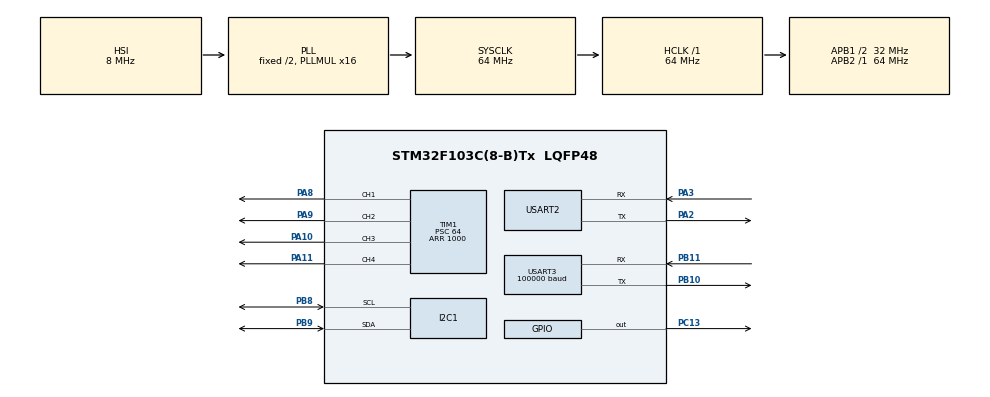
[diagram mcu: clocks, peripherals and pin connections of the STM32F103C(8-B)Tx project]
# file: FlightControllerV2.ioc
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Dma.Request0=USART3_RX
Dma.USART3_RX.0.Direction=DMA_PERIPH_TO_MEMORY
Dma.USART3_RX.0.Instance=DMA1_Channel3
Dma.USART3_RX.0.MemDataAlignment=DMA_MDATAALIGN_BYTE
Dma.USART3_RX.0.MemInc=DMA_MINC_ENABLE
Dma.USART3_RX.0.Mode=DMA_CIRCULAR
Dma.USART3_RX.0.PeriphDataAlignment=DMA_PDATAALIGN_BYTE
Dma.USART3_RX.0.PeriphInc=DMA_PINC_DISABLE
Dma.USART3_RX.0.Priority=DMA_PRIORITY_HIGH
Mcu.Family=STM32F1
Mcu.Name=STM32F103C(8-B)Tx
Mcu.Package=LQFP48
NVIC.DMA1_Channel3_IRQn=true\:1\:0\:true\:false\:true\:false
NVIC.PriorityGroup=NVIC_PRIORITYGROUP_4
NVIC.USART3_IRQn=true\:1\:0\:true\:false\:true\:true
PA10.GPIO_Speed=GPIO_SPEED_FREQ_HIGH
PA10.Signal=S_TIM1_CH3
PA11.GPIO_Speed=GPIO_SPEED_FREQ_HIGH
PA11.Signal=S_TIM1_CH4
PA13.Signal=SYS_JTMS-SWDIO
PA14.Signal=SYS_JTCK-SWCLK
PA2.Mode=Asynchronous
PA2.Signal=USART2_TX
PA3.Mode=Asynchronous
PA3.Signal=USART2_RX
PA8.GPIO_ModeDefaultPP=GPIO_MODE_AF_PP
PA8.GPIO_Speed=GPIO_SPEED_FREQ_HIGH
PA8.Signal=S_TIM1_CH1
PA9.GPIO_Speed=GPIO_SPEED_FREQ_HIGH
PA9.Signal=S_TIM1_CH2
PB10.Mode=Asynchronous
PB10.Signal=USART3_TX
PB11.Mode=Asynchronous
PB11.Signal=USART3_RX
PB8.Mode=I2C
PB8.Signal=I2C1_SCL
PB9.Mode=I2C
PB9.Signal=I2C1_SDA
PC13-TAMPER-RTC.Signal=GPIO_Output
ProjectManager.HeapSize=0x200
ProjectManager.StackSize=0x400
ProjectManager.TargetToolchain=EWARM V7
RCC.AHBFreq_Value=64000000
RCC.APB1CLKDivider=RCC_HCLK_DIV2
RCC.APB1Freq_Value=32000000
RCC.APB1TimFreq_Value=64000000
RCC.APB2Freq_Value=64000000
RCC.APB2TimFreq_Value=64000000
RCC.HCLKFreq_Value=64000000
RCC.PLLMUL=RCC_PLL_MUL16
RCC.SYSCLKFreq_VALUE=64000000
RCC.SYSCLKSource=RCC_SYSCLKSOURCE_PLLCLK
RCC.USBFreq_Value=64000000
SH.S_TIM1_CH1.0=TIM1_CH1,PWM Generation1 CH1
SH.S_TIM1_CH2.0=TIM1_CH2,PWM Generation2 CH2
SH.S_TIM1_CH3.0=TIM1_CH3,PWM Generation3 CH3
SH.S_TIM1_CH4.0=TIM1_CH4,PWM Generation4 CH4
TIM1.Channel-PWM\ Generation1\ CH1=TIM_CHANNEL_1
TIM1.Channel-PWM\ Generation2\ CH2=TIM_CHANNEL_2
TIM1.Channel-PWM\ Generation3\ CH3=TIM_CHANNEL_3
TIM1.Channel-PWM\ Generation4\ CH4=TIM_CHANNEL_4
TIM1.OCFastMode_PWM-PWM\ Generation2\ CH2=TIM_OCFAST_DISABLE
TIM1.Period=1000
TIM1.Prescaler=64
USART2.VirtualMode=VM_ASYNC
USART3.BaudRate=100000
USART3.Parity=PARITY_EVEN
USART3.StopBits=STOPBITS_2
USART3.VirtualMode=VM_ASYNC
USART3.WordLength=WORDLENGTH_9B
VP_SYS_VS_ND.Mode=No_Debug
VP_TIM1_VS_ClockSourceINT.Mode=Internal
board=custom

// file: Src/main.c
/* USER CODE BEGIN Header */
/**
******************************************************************************
* @file           : main.c
* @brief          : Main program body
******************************************************************************
** This notice applies to any and all portions of this file
* that are not between comment pairs USER CODE BEGIN and
* USER CODE END. Other portions of this file, whether
* inserted by the user or by software development tools
* are owned by their respective copyright owners.
*
* COPYRIGHT(c) 2019 STMicroelectronics
*
* Redistribution and use in source and binary forms, with or without modification,
* are permitted provided that the following conditions are met:
*   1. Redistributions of source code must retain the above copyright notice,
*      this list of conditions and the following disclaimer.
*   2. Redistributions in binary form must reproduce the above copyright notice,
*      this list of conditions and the following disclaimer in the documentation
*      and/or other materials provided with the distribution.
*   3. Neither the name of STMicroelectronics nor the names of its contributors
*      may be used to endorse or promote products derived from this software
*      without specific prior written permission.
*
* THIS SOFTWARE IS PROVIDED BY THE COPYRIGHT HOLDERS AND CONTRIBUTORS "AS IS"
* AND ANY EXPRESS OR IMPLIED WARRANTIES, INCLUDING, BUT NOT LIMITED TO, THE
* IMPLIED WARRANTIES OF MERCHANTABILITY AND FITNESS FOR A PARTICULAR PURPOSE ARE
* DISCLAIMED. IN NO EVENT SHALL THE COPYRIGHT HOLDER OR CONTRIBUTORS BE LIABLE
* FOR ANY DIRECT, INDIRECT, INCIDENTAL, SPECIAL, EXEMPLARY, OR CONSEQUENTIAL
* DAMAGES (INCLUDING, BUT NOT LIMITED TO, PROCUREMENT OF SUBSTITUTE GOODS OR
* SERVICES; LOSS OF USE, DATA, OR PROFITS; OR BUSINESS INTERRUPTION) HOWEVER
* CAUSED AND ON ANY THEORY OF LIABILITY, WHETHER IN CONTRACT, STRICT LIABILITY,
* OR TORT (INCLUDING NEGLIGENCE OR OTHERWISE) ARISING IN ANY WAY OUT OF THE USE
* OF THIS SOFTWARE, EVEN IF ADVISED OF THE POSSIBILITY OF SUCH DAMAGE.
*
******************************************************************************
*/
/* USER CODE END Header */

#include "main.h"

/* USER CODE BEGIN Includes */
#include "main_app.h"
#include "led.h"
#include "test_app.h"
/* USER CODE END Includes */

I2C_HandleTypeDef hi2c1;

TIM_HandleTypeDef htim1;

UART_HandleTypeDef huart2;
UART_HandleTypeDef huart3;
DMA_HandleTypeDef hdma_usart3_rx;

void SystemClock_Config(void);
static void MX_GPIO_Init(void);
static void MX_DMA_Init(void);
static void MX_I2C1_Init(void);
static void MX_TIM1_Init(void);
static void MX_USART3_UART_Init(void);
static void MX_USART2_UART_Init(void);

int main(void)
{

    /* MCU Configuration--------------------------------------------------------*/

    /* Reset of all peripherals, Initializes the Flash interface and the Systick. */
    HAL_Init();

    /* Configure the system clock */
    SystemClock_Config();

    /* Initialize all configured peripherals */
    MX_GPIO_Init();
    MX_DMA_Init();
    MX_I2C1_Init();
    MX_TIM1_Init();
    MX_USART3_UART_Init();
    MX_USART2_UART_Init();
    /* USER CODE BEGIN 2 */
    HAL_Delay(1000);
    MainApp(); //runs my flight controller app
    // TestMadgwickNoMag_Main();
    /* USER CODE END 2 */

    /* Infinite loop */
    while (1)
    {

    }
}

void SystemClock_Config(void)
{
    RCC_OscInitTypeDef RCC_OscInitStruct = {0};
    RCC_ClkInitTypeDef RCC_ClkInitStruct = {0};

    /**Initializes the CPU, AHB and APB busses clocks
    */
    RCC_OscInitStruct.OscillatorType = RCC_OSCILLATORTYPE_HSI;
    RCC_OscInitStruct.HSIState = RCC_HSI_ON;
    RCC_OscInitStruct.HSICalibrationValue = RCC_HSICALIBRATION_DEFAULT;
    RCC_OscInitStruct.PLL.PLLState = RCC_PLL_ON;
    RCC_OscInitStruct.PLL.PLLSource = RCC_PLLSOURCE_HSI_DIV2;
    RCC_OscInitStruct.PLL.PLLMUL = RCC_PLL_MUL16;
    if (HAL_RCC_OscConfig(&RCC_OscInitStruct) != HAL_OK)
    {
        Error_Handler();
    }
    /**Initializes the CPU, AHB and APB busses clocks
    */
    RCC_ClkInitStruct.ClockType = RCC_CLOCKTYPE_HCLK|RCC_CLOCKTYPE_SYSCLK
        |RCC_CLOCKTYPE_PCLK1|RCC_CLOCKTYPE_PCLK2;
    RCC_ClkInitStruct.SYSCLKSource = RCC_SYSCLKSOURCE_PLLCLK;
    RCC_ClkInitStruct.AHBCLKDivider = RCC_SYSCLK_DIV1;
    RCC_ClkInitStruct.APB1CLKDivider = RCC_HCLK_DIV2;
    RCC_ClkInitStruct.APB2CLKDivider = RCC_HCLK_DIV1;

    if (HAL_RCC_ClockConfig(&RCC_ClkInitStruct, FLASH_LATENCY_2) != HAL_OK)
    {
        Error_Handler();
    }
}

static void MX_I2C1_Init(void)
{

    hi2c1.Instance = I2C1;
    hi2c1.Init.ClockSpeed = 100000;
    hi2c1.Init.DutyCycle = I2C_DUTYCYCLE_2;
    hi2c1.Init.OwnAddress1 = 0;
    hi2c1.Init.AddressingMode = I2C_ADDRESSINGMODE_7BIT;
    hi2c1.Init.DualAddressMode = I2C_DUALADDRESS_DISABLE;
    hi2c1.Init.OwnAddress2 = 0;
    hi2c1.Init.GeneralCallMode = I2C_GENERALCALL_DISABLE;
    hi2c1.Init.NoStretchMode = I2C_NOSTRETCH_DISABLE;
    if (HAL_I2C_Init(&hi2c1) != HAL_OK)
    {
        Error_Handler();
    }

}

static void MX_TIM1_Init(void)
{

    TIM_ClockConfigTypeDef sClockSourceConfig = {0};
    TIM_MasterConfigTypeDef sMasterConfig = {0};
    TIM_OC_InitTypeDef sConfigOC = {0};
    TIM_BreakDeadTimeConfigTypeDef sBreakDeadTimeConfig = {0};

    htim1.Instance = TIM1;
    htim1.Init.Prescaler = 64;
    htim1.Init.CounterMode = TIM_COUNTERMODE_UP;
    htim1.Init.Period = 5000;
    htim1.Init.ClockDivision = TIM_CLOCKDIVISION_DIV1;
    htim1.Init.RepetitionCounter = 0;
    htim1.Init.AutoReloadPreload = TIM_AUTORELOAD_PRELOAD_DISABLE;
    if (HAL_TIM_Base_Init(&htim1) != HAL_OK)
    {
        Error_Handler();
    }
    sClockSourceConfig.ClockSource = TIM_CLOCKSOURCE_INTERNAL;
    if (HAL_TIM_ConfigClockSource(&htim1, &sClockSourceConfig) != HAL_OK)
    {
        Error_Handler();
    }
    if (HAL_TIM_PWM_Init(&htim1) != HAL_OK)
    {
        Error_Handler();
    }
    sMasterConfig.MasterOutputTrigger = TIM_TRGO_RESET;
    sMasterConfig.MasterSlaveMode = TIM_MASTERSLAVEMODE_DISABLE;
    if (HAL_TIMEx_MasterConfigSynchronization(&htim1, &sMasterConfig) != HAL_OK)
    {
        Error_Handler();
    }
    sConfigOC.OCMode = TIM_OCMODE_PWM1;
    sConfigOC.Pulse = 0;
    sConfigOC.OCPolarity = TIM_OCPOLARITY_HIGH;
    sConfigOC.OCNPolarity = TIM_OCNPOLARITY_HIGH;
    sConfigOC.OCFastMode = TIM_OCFAST_DISABLE;
    sConfigOC.OCIdleState = TIM_OCIDLESTATE_RESET;
    sConfigOC.OCNIdleState = TIM_OCNIDLESTATE_RESET;
    if (HAL_TIM_PWM_ConfigChannel(&htim1, &sConfigOC, TIM_CHANNEL_1) != HAL_OK)
    {
        Error_Handler();
    }
    if (HAL_TIM_PWM_ConfigChannel(&htim1, &sConfigOC, TIM_CHANNEL_2) != HAL_OK)
    {
        Error_Handler();
    }
    if (HAL_TIM_PWM_ConfigChannel(&htim1, &sConfigOC, TIM_CHANNEL_3) != HAL_OK)
    {
        Error_Handler();
    }
    if (HAL_TIM_PWM_ConfigChannel(&htim1, &sConfigOC, TIM_CHANNEL_4) != HAL_OK)
    {
        Error_Handler();
    }
    sBreakDeadTimeConfig.OffStateRunMode = TIM_OSSR_DISABLE;
    sBreakDeadTimeConfig.OffStateIDLEMode = TIM_OSSI_DISABLE;
    sBreakDeadTimeConfig.LockLevel = TIM_LOCKLEVEL_OFF;
    sBreakDeadTimeConfig.DeadTime = 0;
    sBreakDeadTimeConfig.BreakState = TIM_BREAK_DISABLE;
    sBreakDeadTimeConfig.BreakPolarity = TIM_BREAKPOLARITY_HIGH;
    sBreakDeadTimeConfig.AutomaticOutput = TIM_AUTOMATICOUTPUT_DISABLE;
    if (HAL_TIMEx_ConfigBreakDeadTime(&htim1, &sBreakDeadTimeConfig) != HAL_OK)
    {
        Error_Handler();
    }
    HAL_TIM_MspPostInit(&htim1);

}

static void MX_USART2_UART_Init(void)
{

    huart2.Instance = USART2;
    huart2.Init.BaudRate = 115200;
    huart2.Init.WordLength = UART_WORDLENGTH_8B;
    huart2.Init.StopBits = UART_STOPBITS_1;
    huart2.Init.Parity = UART_PARITY_NONE;
    huart2.Init.Mode = UART_MODE_TX_RX;
    huart2.Init.HwFlowCtl = UART_HWCONTROL_NONE;
    huart2.Init.OverSampling = UART_OVERSAMPLING_16;
    if (HAL_UART_Init(&huart2) != HAL_OK)
    {
        Error_Handler();
    }

}

static void MX_USART3_UART_Init(void)
{

    huart3.Instance = USART3;
    huart3.Init.BaudRate = 100000;
    huart3.Init.WordLength = UART_WORDLENGTH_9B;
    huart3.Init.StopBits = UART_STOPBITS_2;
    huart3.Init.Parity = UART_PARITY_EVEN;
    huart3.Init.Mode = UART_MODE_TX_RX;
    huart3.Init.HwFlowCtl = UART_HWCONTROL_NONE;
    huart3.Init.OverSampling = UART_OVERSAMPLING_16;
    if (HAL_UART_Init(&huart3) != HAL_OK)
    {
        Error_Handler();
    }

}

static void MX_DMA_Init(void)
{
    /* DMA controller clock enable */
    __HAL_RCC_DMA1_CLK_ENABLE();

    /* DMA interrupt init */
    /* DMA1_Channel3_IRQn interrupt configuration */
    HAL_NVIC_SetPriority(DMA1_Channel3_IRQn, 1, 0);
    HAL_NVIC_EnableIRQ(DMA1_Channel3_IRQn);

}

static void MX_GPIO_Init(void)
{
    GPIO_InitTypeDef GPIO_InitStruct = {0};

    /* GPIO Ports Clock Enable */
    __HAL_RCC_GPIOC_CLK_ENABLE();
    __HAL_RCC_GPIOA_CLK_ENABLE();
    __HAL_RCC_GPIOB_CLK_ENABLE();

    /*Configure GPIO pin Output Level */
    HAL_GPIO_WritePin(GPIOC, GPIO_PIN_13, GPIO_PIN_RESET);

    /*Configure GPIO pin : PC13 */
    GPIO_InitStruct.Pin = GPIO_PIN_13;
    GPIO_InitStruct.Mode = GPIO_MODE_OUTPUT_PP;
    GPIO_InitStruct.Pull = GPIO_NOPULL;
    GPIO_InitStruct.Speed = GPIO_SPEED_FREQ_LOW;
    HAL_GPIO_Init(GPIOC, &GPIO_InitStruct);

}

void Error_Handler(void)
{
}

/************************ (C) COPYRIGHT STMicroelectronics *****END OF FILE****/
